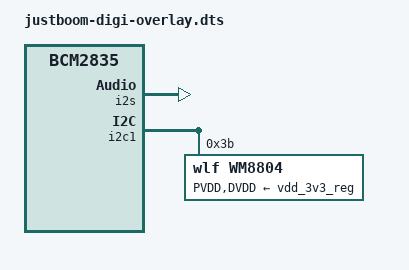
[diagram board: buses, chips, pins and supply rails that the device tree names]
// Definitions for JustBoom Digi
/dts-v1/;
/plugin/;

/ {
	compatible = "brcm,bcm2835";

	fragment@0 {
		target = <&i2s>;
		__overlay__ {
			status = "okay";
		};
	};

	fragment@1 {
		target = <&i2c1>;
		__overlay__ {
			#address-cells = <1>;
			#size-cells = <0>;
			status = "okay";

			wm8804@3b {
				#sound-dai-cells = <0>;
				compatible = "wlf,wm8804";
				reg = <0x3b>;
				PVDD-supply = <&vdd_3v3_reg>;
				DVDD-supply = <&vdd_3v3_reg>;
				status = "okay";
			};
		};
	};

	fragment@2 {
		target = <&sound>;
		__overlay__ {
			compatible = "justboom,justboom-digi";
			i2s-controller = <&i2s>;
			status = "okay";
		};
	};
};
